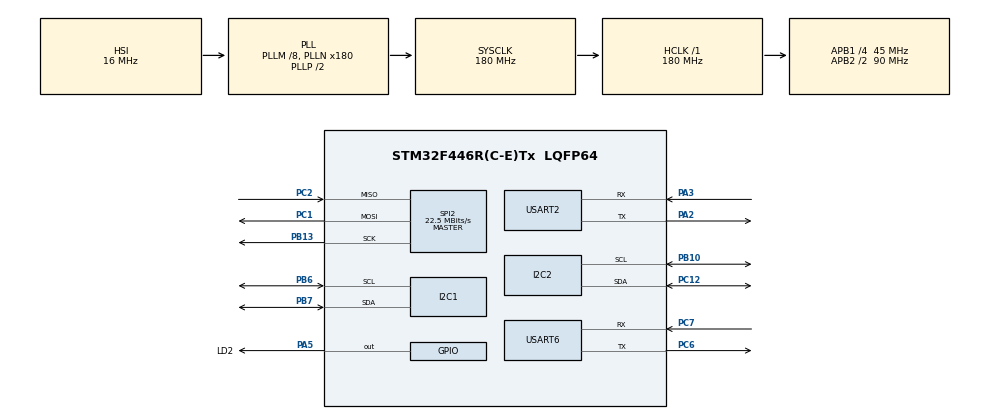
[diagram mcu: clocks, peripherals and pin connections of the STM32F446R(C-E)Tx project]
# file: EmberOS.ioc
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Dma.Request0=USART6_RX
Dma.Request1=USART2_TX
Dma.USART2_TX.1.Direction=DMA_MEMORY_TO_PERIPH
Dma.USART2_TX.1.FIFOMode=DMA_FIFOMODE_DISABLE
Dma.USART2_TX.1.Instance=DMA1_Stream6
Dma.USART2_TX.1.MemDataAlignment=DMA_MDATAALIGN_BYTE
Dma.USART2_TX.1.MemInc=DMA_MINC_ENABLE
Dma.USART2_TX.1.Mode=DMA_NORMAL
Dma.USART2_TX.1.PeriphDataAlignment=DMA_PDATAALIGN_BYTE
Dma.USART2_TX.1.PeriphInc=DMA_PINC_DISABLE
Dma.USART2_TX.1.Priority=DMA_PRIORITY_HIGH
Dma.USART6_RX.0.Direction=DMA_PERIPH_TO_MEMORY
Dma.USART6_RX.0.FIFOMode=DMA_FIFOMODE_DISABLE
Dma.USART6_RX.0.Instance=DMA2_Stream1
Dma.USART6_RX.0.MemDataAlignment=DMA_MDATAALIGN_BYTE
Dma.USART6_RX.0.MemInc=DMA_MINC_ENABLE
Dma.USART6_RX.0.Mode=DMA_CIRCULAR
Dma.USART6_RX.0.PeriphDataAlignment=DMA_PDATAALIGN_BYTE
Dma.USART6_RX.0.PeriphInc=DMA_PINC_DISABLE
Dma.USART6_RX.0.Priority=DMA_PRIORITY_HIGH
FREERTOS.Tasks01=defaultTask,24,128,StartDefaultTask,Default,NULL,Dynamic,NULL,NULL;SensorTask,32,512,StartSensorTask,Default,NULL,Dynamic,NULL,NULL;TelemetryTask,39,128,StartTask03,Default,NULL,Dynamic,NULL,NULL
FREERTOS.configUSE_NEWLIB_REENTRANT=1
Mcu.Family=STM32F4
Mcu.Name=STM32F446R(C-E)Tx
Mcu.Package=LQFP64
NVIC.DMA1_Stream6_IRQn=true\:5\:0\:false\:false\:true\:true\:false\:true\:true
NVIC.DMA2_Stream1_IRQn=true\:5\:0\:false\:false\:true\:true\:false\:true\:true
NVIC.PriorityGroup=NVIC_PRIORITYGROUP_4
NVIC.TIM6_DAC_IRQn=true\:15\:0\:false\:false\:true\:false\:false\:true\:true
NVIC.TimeBase=TIM6_DAC_IRQn
NVIC.TimeBaseIP=TIM6
NVIC.USART2_IRQn=true\:5\:0\:false\:false\:true\:true\:true\:true\:true
PA13.Mode=Serial_Wire
PA13.Signal=SYS_JTMS-SWDIO
PA14.Mode=Serial_Wire
PA14.Signal=SYS_JTCK-SWCLK
PA2.Mode=Asynchronous
PA2.Signal=USART2_TX
PA3.Mode=Asynchronous
PA3.Signal=USART2_RX
PA5.GPIO_Label=LD2
PA5.Signal=GPIO_Output
PB10.Mode=I2C
PB10.Signal=I2C2_SCL
PB13.Mode=Full_Duplex_Master
PB13.Signal=SPI2_SCK
PB6.Mode=I2C
PB6.Signal=I2C1_SCL
PB7.Mode=I2C
PB7.Signal=I2C1_SDA
PC1.Mode=Full_Duplex_Master
PC1.Signal=SPI2_MOSI
PC12.Mode=I2C
PC12.Signal=I2C2_SDA
PC2.Mode=Full_Duplex_Master
PC2.Signal=SPI2_MISO
PC6.Mode=Asynchronous
PC6.Signal=USART6_TX
PC7.Mode=Asynchronous
PC7.Signal=USART6_RX
ProjectManager.HeapSize=0x200
ProjectManager.StackSize=0x400
ProjectManager.TargetToolchain=STM32CubeIDE
RCC.AHBFreq_Value=180000000
RCC.APB1CLKDivider=RCC_HCLK_DIV4
RCC.APB1Freq_Value=45000000
RCC.APB1TimFreq_Value=90000000
RCC.APB2CLKDivider=RCC_HCLK_DIV2
RCC.APB2Freq_Value=90000000
RCC.APB2TimFreq_Value=180000000
RCC.CortexFreq_Value=180000000
RCC.HCLKFreq_Value=180000000
RCC.PLLM=8
RCC.PLLN=180
RCC.SYSCLKFreq_VALUE=180000000
RCC.SYSCLKSource=RCC_SYSCLKSOURCE_PLLCLK
RCC.USBFreq_Value=180000000
RCC.VCOOutputFreq_Value=360000000
SPI2.CalculateBaudRate=22.5 MBits/s
SPI2.Direction=SPI_DIRECTION_2LINES
SPI2.Mode=SPI_MODE_MASTER
SPI2.VirtualType=VM_MASTER
USART2.VirtualMode=VM_ASYNC
USART6.VirtualMode=VM_ASYNC
VP_FREERTOS_VS_CMSIS_V2.Mode=CMSIS_V2
VP_SYS_VS_tim6.Mode=TIM6
board=custom

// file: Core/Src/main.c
/* USER CODE BEGIN Header */
/**
  ******************************************************************************
  * @file           : main.c
  * @brief          : Main program body
  ******************************************************************************
  * @attention
  *
  * Copyright (c) 2026 STMicroelectronics.
  * All rights reserved.
  *
  * This software is licensed under terms that can be found in the LICENSE file
  * in the root directory of this software component.
  * If no LICENSE file comes with this software, it is provided AS-IS.
  *
  ******************************************************************************
  */
/* USER CODE END Header */
#include "main.h"
#include "cmsis_os.h"

/* USER CODE BEGIN Includes */
#include "AppMain.h"
#include <stdio.h>
/* USER CODE END Includes */

I2C_HandleTypeDef hi2c1;
I2C_HandleTypeDef hi2c2;

SPI_HandleTypeDef hspi2;

UART_HandleTypeDef huart2;
UART_HandleTypeDef huart6;
DMA_HandleTypeDef hdma_usart2_tx;
DMA_HandleTypeDef hdma_usart6_rx;

/* Definitions for defaultTask */
osThreadId_t defaultTaskHandle;
const osThreadAttr_t defaultTask_attributes = {
  .name = "defaultTask",
  .stack_size = 128 * 4,
  .priority = (osPriority_t) osPriorityNormal,
};
/* Definitions for SensorTask */
osThreadId_t SensorTaskHandle;
const osThreadAttr_t SensorTask_attributes = {
  .name = "SensorTask",
  .stack_size = 512 * 4,
  .priority = (osPriority_t) osPriorityAboveNormal,
};
/* Definitions for TelemetryTask */
osThreadId_t TelemetryTaskHandle;
const osThreadAttr_t TelemetryTask_attributes = {
  .name = "TelemetryTask",
  .stack_size = 128 * 4,
  .priority = (osPriority_t) osPriorityAboveNormal7,
};

void SystemClock_Config(void);
static void MX_GPIO_Init(void);
static void MX_DMA_Init(void);
static void MX_USART2_UART_Init(void);
static void MX_I2C1_Init(void);
static void MX_I2C2_Init(void);
static void MX_SPI2_Init(void);
static void MX_USART6_UART_Init(void);
void StartDefaultTask(void *argument);
void StartSensorTask(void *argument);
void StartTask03(void *argument);

int main(void)
{

  /* MCU Configuration--------------------------------------------------------*/

  /* Reset of all peripherals, Initializes the Flash interface and the Systick. */
  HAL_Init();

  /* Configure the system clock */
  SystemClock_Config();

  /* Initialize all configured peripherals */
  MX_GPIO_Init();
  MX_DMA_Init();
  MX_USART2_UART_Init();
  MX_I2C1_Init();
  MX_I2C2_Init();
  MX_SPI2_Init();
  MX_USART6_UART_Init();
  /* USER CODE BEGIN 2 */
  App_Main_Start();
  /* USER CODE END 2 */

  /* Init scheduler */
  osKernelInitialize();

  /* Create the thread(s) */
  /* creation of defaultTask */
  defaultTaskHandle = osThreadNew(StartDefaultTask, NULL, &defaultTask_attributes);

  /* creation of SensorTask */
  SensorTaskHandle = osThreadNew(StartSensorTask, NULL, &SensorTask_attributes);

  /* creation of TelemetryTask */
  TelemetryTaskHandle = osThreadNew(StartTask03, NULL, &TelemetryTask_attributes);

  /* Start scheduler */
  osKernelStart();

  /* We should never get here as control is now taken by the scheduler */

  /* Infinite loop */
  while (1)
  {

  }
}

void SystemClock_Config(void)
{
  RCC_OscInitTypeDef RCC_OscInitStruct = {0};
  RCC_ClkInitTypeDef RCC_ClkInitStruct = {0};

  /** Configure the main internal regulator output voltage
  */
  __HAL_RCC_PWR_CLK_ENABLE();
  __HAL_PWR_VOLTAGESCALING_CONFIG(PWR_REGULATOR_VOLTAGE_SCALE1);

  /** Initializes the RCC Oscillators according to the specified parameters
  * in the RCC_OscInitTypeDef structure.
  */
  RCC_OscInitStruct.OscillatorType = RCC_OSCILLATORTYPE_HSI;
  RCC_OscInitStruct.HSIState = RCC_HSI_ON;
  RCC_OscInitStruct.HSICalibrationValue = RCC_HSICALIBRATION_DEFAULT;
  RCC_OscInitStruct.PLL.PLLState = RCC_PLL_ON;
  RCC_OscInitStruct.PLL.PLLSource = RCC_PLLSOURCE_HSI;
  RCC_OscInitStruct.PLL.PLLM = 8;
  RCC_OscInitStruct.PLL.PLLN = 180;
  RCC_OscInitStruct.PLL.PLLP = RCC_PLLP_DIV2;
  RCC_OscInitStruct.PLL.PLLQ = 2;
  RCC_OscInitStruct.PLL.PLLR = 2;
  if (HAL_RCC_OscConfig(&RCC_OscInitStruct) != HAL_OK)
  {
    Error_Handler();
  }

  /** Activate the Over-Drive mode
  */
  if (HAL_PWREx_EnableOverDrive() != HAL_OK)
  {
    Error_Handler();
  }

  /** Initializes the CPU, AHB and APB buses clocks
  */
  RCC_ClkInitStruct.ClockType = RCC_CLOCKTYPE_HCLK|RCC_CLOCKTYPE_SYSCLK
                              |RCC_CLOCKTYPE_PCLK1|RCC_CLOCKTYPE_PCLK2;
  RCC_ClkInitStruct.SYSCLKSource = RCC_SYSCLKSOURCE_PLLCLK;
  RCC_ClkInitStruct.AHBCLKDivider = RCC_SYSCLK_DIV1;
  RCC_ClkInitStruct.APB1CLKDivider = RCC_HCLK_DIV4;
  RCC_ClkInitStruct.APB2CLKDivider = RCC_HCLK_DIV2;

  if (HAL_RCC_ClockConfig(&RCC_ClkInitStruct, FLASH_LATENCY_5) != HAL_OK)
  {
    Error_Handler();
  }
}

static void MX_I2C1_Init(void)
{

  hi2c1.Instance = I2C1;
  hi2c1.Init.ClockSpeed = 100000;
  hi2c1.Init.DutyCycle = I2C_DUTYCYCLE_2;
  hi2c1.Init.OwnAddress1 = 0;
  hi2c1.Init.AddressingMode = I2C_ADDRESSINGMODE_7BIT;
  hi2c1.Init.DualAddressMode = I2C_DUALADDRESS_DISABLE;
  hi2c1.Init.OwnAddress2 = 0;
  hi2c1.Init.GeneralCallMode = I2C_GENERALCALL_DISABLE;
  hi2c1.Init.NoStretchMode = I2C_NOSTRETCH_DISABLE;
  if (HAL_I2C_Init(&hi2c1) != HAL_OK)
  {
    Error_Handler();
  }

}

static void MX_I2C2_Init(void)
{

  hi2c2.Instance = I2C2;
  hi2c2.Init.ClockSpeed = 100000;
  hi2c2.Init.DutyCycle = I2C_DUTYCYCLE_2;
  hi2c2.Init.OwnAddress1 = 0;
  hi2c2.Init.AddressingMode = I2C_ADDRESSINGMODE_7BIT;
  hi2c2.Init.DualAddressMode = I2C_DUALADDRESS_DISABLE;
  hi2c2.Init.OwnAddress2 = 0;
  hi2c2.Init.GeneralCallMode = I2C_GENERALCALL_DISABLE;
  hi2c2.Init.NoStretchMode = I2C_NOSTRETCH_DISABLE;
  if (HAL_I2C_Init(&hi2c2) != HAL_OK)
  {
    Error_Handler();
  }

}

static void MX_SPI2_Init(void)
{

  /* SPI2 parameter configuration*/
  hspi2.Instance = SPI2;
  hspi2.Init.Mode = SPI_MODE_MASTER;
  hspi2.Init.Direction = SPI_DIRECTION_2LINES;
  hspi2.Init.DataSize = SPI_DATASIZE_8BIT;
  hspi2.Init.CLKPolarity = SPI_POLARITY_LOW;
  hspi2.Init.CLKPhase = SPI_PHASE_1EDGE;
  hspi2.Init.NSS = SPI_NSS_SOFT;
  hspi2.Init.BaudRatePrescaler = SPI_BAUDRATEPRESCALER_2;
  hspi2.Init.FirstBit = SPI_FIRSTBIT_MSB;
  hspi2.Init.TIMode = SPI_TIMODE_DISABLE;
  hspi2.Init.CRCCalculation = SPI_CRCCALCULATION_DISABLE;
  hspi2.Init.CRCPolynomial = 10;
  if (HAL_SPI_Init(&hspi2) != HAL_OK)
  {
    Error_Handler();
  }

}

static void MX_USART2_UART_Init(void)
{

  huart2.Instance = USART2;
  huart2.Init.BaudRate = 115200;
  huart2.Init.WordLength = UART_WORDLENGTH_8B;
  huart2.Init.StopBits = UART_STOPBITS_1;
  huart2.Init.Parity = UART_PARITY_NONE;
  huart2.Init.Mode = UART_MODE_TX_RX;
  huart2.Init.HwFlowCtl = UART_HWCONTROL_NONE;
  huart2.Init.OverSampling = UART_OVERSAMPLING_16;
  if (HAL_UART_Init(&huart2) != HAL_OK)
  {
    Error_Handler();
  }

}

static void MX_USART6_UART_Init(void)
{

  huart6.Instance = USART6;
  huart6.Init.BaudRate = 115200;
  huart6.Init.WordLength = UART_WORDLENGTH_8B;
  huart6.Init.StopBits = UART_STOPBITS_1;
  huart6.Init.Parity = UART_PARITY_NONE;
  huart6.Init.Mode = UART_MODE_TX_RX;
  huart6.Init.HwFlowCtl = UART_HWCONTROL_NONE;
  huart6.Init.OverSampling = UART_OVERSAMPLING_16;
  if (HAL_UART_Init(&huart6) != HAL_OK)
  {
    Error_Handler();
  }

}

static void MX_DMA_Init(void)
{

  /* DMA controller clock enable */
  __HAL_RCC_DMA2_CLK_ENABLE();
  __HAL_RCC_DMA1_CLK_ENABLE();

  /* DMA interrupt init */
  /* DMA1_Stream6_IRQn interrupt configuration */
  HAL_NVIC_SetPriority(DMA1_Stream6_IRQn, 5, 0);
  HAL_NVIC_EnableIRQ(DMA1_Stream6_IRQn);
  /* DMA2_Stream1_IRQn interrupt configuration */
  HAL_NVIC_SetPriority(DMA2_Stream1_IRQn, 5, 0);
  HAL_NVIC_EnableIRQ(DMA2_Stream1_IRQn);

}

static void MX_GPIO_Init(void)
{
  GPIO_InitTypeDef GPIO_InitStruct = {0};

  /* GPIO Ports Clock Enable */
  __HAL_RCC_GPIOC_CLK_ENABLE();
  __HAL_RCC_GPIOA_CLK_ENABLE();
  __HAL_RCC_GPIOB_CLK_ENABLE();

  /*Configure GPIO pin Output Level */
  HAL_GPIO_WritePin(LD2_GPIO_Port, LD2_Pin, GPIO_PIN_RESET);

  /*Configure GPIO pin : LD2_Pin */
  GPIO_InitStruct.Pin = LD2_Pin;
  GPIO_InitStruct.Mode = GPIO_MODE_OUTPUT_PP;
  GPIO_InitStruct.Pull = GPIO_NOPULL;
  GPIO_InitStruct.Speed = GPIO_SPEED_FREQ_LOW;
  HAL_GPIO_Init(LD2_GPIO_Port, &GPIO_InitStruct);

}

/* USER CODE BEGIN 4 */
#ifdef __GNUC__
int _write(int file, char *ptr, int len)
{
  HAL_UART_Transmit(&huart2, (uint8_t*)ptr, len, HAL_MAX_DELAY);
  return len;
}
#endif
/* USER CODE END 4 */

void StartDefaultTask(void *argument)
{
  /* USER CODE BEGIN 5 */

  /* Infinite loop */
  for(;;)
  {
	  App_Led_Task();
	  osDelay(100);

  }
  /* USER CODE END 5 */
}

void StartSensorTask(void *argument)
{
  /* USER CODE BEGIN StartSensorTask */

  /* Infinite loop */
  for(;;)
  {
	  App_Sensor_Task();
	  osDelay(4);// I decided to 250hz
  }
  /* USER CODE END StartSensorTask */
}

void StartTask03(void *argument)
{
  for(;;)
  {
    osDelay(1);
  }
}

void HAL_TIM_PeriodElapsedCallback(TIM_HandleTypeDef *htim)
{
  if (htim->Instance == TIM6)
  {
    HAL_IncTick();
  }
}

void Error_Handler(void)
{
  __disable_irq();
  while (1)
  {
  }
}
